# MSEBIS register map
Registers from a debugger description file.
Registers are 32-bit, access not given, no defined reset value unless marked. A register's access mark holds for its fields unless they carry their own. Addresses are absolute; registers are grouped by the start of their names; lines under a group give offsets from that group; [hi:lo] are bit positions; {n}, {i} and the like mark numbered series; 'fields as' and 'values as' point back to an identical list; <NAME> marks a mode.

## rMSEBIS
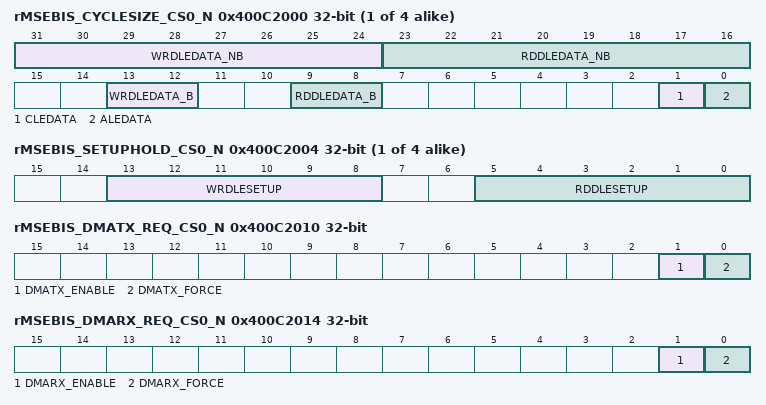
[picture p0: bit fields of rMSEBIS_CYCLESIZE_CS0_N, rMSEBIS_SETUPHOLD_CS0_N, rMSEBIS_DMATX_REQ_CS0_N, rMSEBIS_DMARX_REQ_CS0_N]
{0x400C2000+0x100*i} rMSEBIS_CYCLESIZE_CS{i}_N (i=0..3)
  [31:24] WRDLEDATA_NB, [23:16] RDDLEDATA_NB, [13:12] WRDLEDATA_B, [9:8] RDDLEDATA_B, [1] CLEDATA, [0] ALEDATA
{0x400C2004+0x100*i} rMSEBIS_SETUPHOLD_CS{i}_N (i=0..3)
  [13:8] WRDLESETUP, [5:0] RDDLESETUP
{0x400C2008+0x100*i} rMSEBIS_MMU_ADDR_CS{i}_N (i=0..3)
  [31:12] MMU_ADDR
{0x400C200C+0x100*i} rMSEBIS_MMU_ADDR_MASK_CS{i}_N (i=0..3)
  [31:12] MMU_ADDR_MASK
0x400C2010 rMSEBIS_DMATX_REQ_CS0_N
  [1] DMATX_ENABLE, [0] DMATX_FORCE
0x400C2014 rMSEBIS_DMARX_REQ_CS0_N
  [1] DMARX_ENABLE, [0] DMARX_FORCE
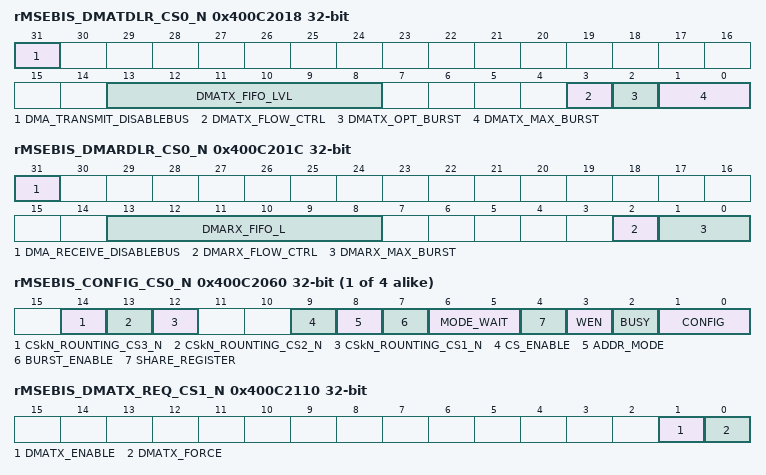
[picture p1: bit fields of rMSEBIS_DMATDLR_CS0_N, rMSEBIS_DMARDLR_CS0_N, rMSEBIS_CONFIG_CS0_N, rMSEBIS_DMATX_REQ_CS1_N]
0x400C2018 rMSEBIS_DMATDLR_CS0_N
  [31] DMA_TRANSMIT_DISABLEBUS, [13:8] DMATX_FIFO_LVL, [3] DMATX_FLOW_CTRL, [2] DMATX_OPT_BURST, [1:0] DMATX_MAX_BURST
0x400C201C rMSEBIS_DMARDLR_CS0_N
  [31] DMA_RECEIVE_DISABLEBUS, [13:8] DMARX_FIFO_L, [2] DMARX_FLOW_CTRL, [1:0] DMARX_MAX_BURST
{0x400C2060+0x100*i} rMSEBIS_CONFIG_CS{i}_N (i=0..3)
  [14] CSkN_ROUNTING_CS3_N, [13] CSkN_ROUNTING_CS2_N, [12] CSkN_ROUNTING_CS1_N, [9] CS_ENABLE, [8] ADDR_MODE, [7] BURST_ENABLE, [6:5] MODE_WAIT, [4] SHARE_REGISTER, [3] WEN, [2] BUSY, [1:0] CONFIG
0x400C2110 rMSEBIS_DMATX_REQ_CS1_N
  [1] DMATX_ENABLE, [0] DMATX_FORCE
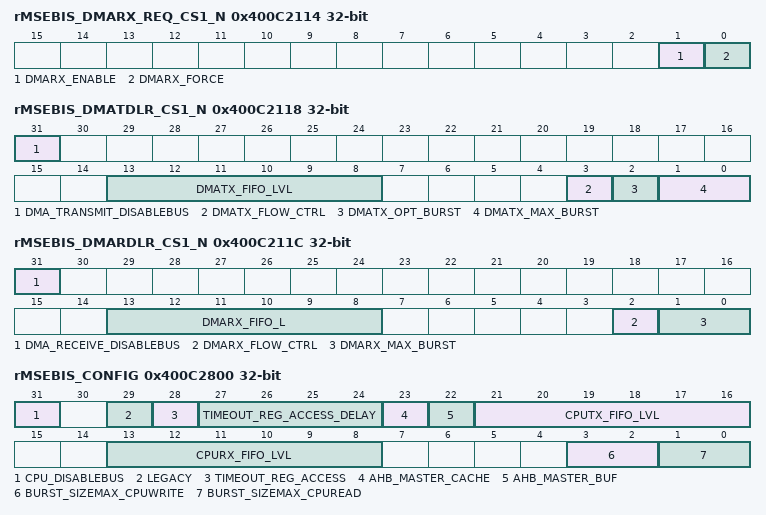
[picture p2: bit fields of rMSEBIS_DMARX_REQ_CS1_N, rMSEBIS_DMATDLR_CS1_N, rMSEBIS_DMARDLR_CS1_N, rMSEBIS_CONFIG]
0x400C2114 rMSEBIS_DMARX_REQ_CS1_N
  [1] DMARX_ENABLE, [0] DMARX_FORCE
0x400C2118 rMSEBIS_DMATDLR_CS1_N
  fields as rMSEBIS_DMATDLR_CS0_N
0x400C211C rMSEBIS_DMARDLR_CS1_N
  fields as rMSEBIS_DMARDLR_CS0_N
0x400C2800 rMSEBIS_CONFIG
  [31] CPU_DISABLEBUS, [29] LEGACY, [28] TIMEOUT_REG_ACCESS, [27:24] TIMEOUT_REG_ACCESS_DELAY, [23] AHB_MASTER_CACHE, [22] AHB_MASTER_BUF, [21:16] CPUTX_FIFO_LVL, [13:8] CPURX_FIFO_LVL, [3:2] BURST_SIZEMAX_CPUWRITE, [1:0] BURST_SIZEMAX_CPUREAD
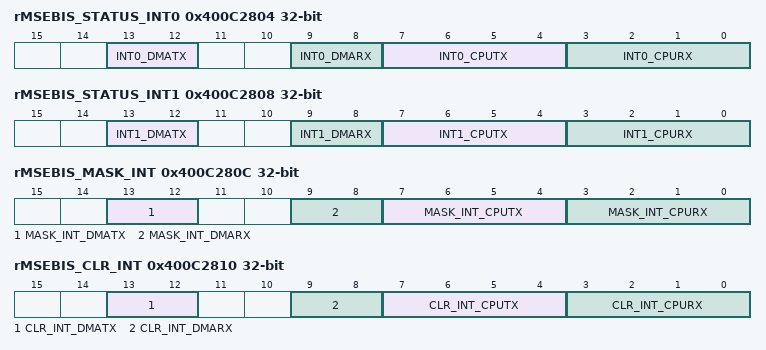
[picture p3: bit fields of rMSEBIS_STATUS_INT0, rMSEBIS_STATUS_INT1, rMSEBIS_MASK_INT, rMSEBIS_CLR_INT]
0x400C2804 rMSEBIS_STATUS_INT0 ro
  [13:12] INT0_DMATX, [9:8] INT0_DMARX, [7:4] INT0_CPUTX, [3:0] INT0_CPURX
0x400C2808 rMSEBIS_STATUS_INT1 ro
  [13:12] INT1_DMATX, [9:8] INT1_DMARX, [7:4] INT1_CPUTX, [3:0] INT1_CPURX
0x400C280C rMSEBIS_MASK_INT
  [13:12] MASK_INT_DMATX, [9:8] MASK_INT_DMARX, [7:4] MASK_INT_CPUTX, [3:0] MASK_INT_CPURX
0x400C2810 rMSEBIS_CLR_INT
  [13:12] CLR_INT_DMATX, [9:8] CLR_INT_DMARX, [7:4] CLR_INT_CPUTX, [3:0] CLR_INT_CPURX
0x400C2814 rMSEBIS_EOB_ADDR
  [31:2] EOB_ADDR
